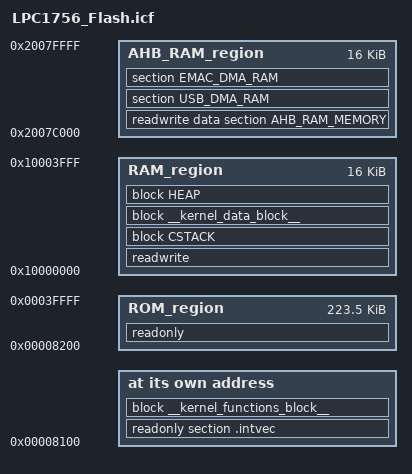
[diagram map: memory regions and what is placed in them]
/*###ICF### Section handled by ICF editor, don't touch! ****/
/*-Editor annotation file-*/
/* IcfEditorFile="$TOOLKIT_DIR$\config\ide\IcfEditor\cortex_v1_0.xml" */
/*-Specials-*/
define symbol __ICFEDIT_intvec_start__ = 0x00008100;
/*-Memory Regions-*/
define symbol __ICFEDIT_region_ROM_start__   = 0x00008200;
define symbol __ICFEDIT_region_ROM_end__     = 0x0003FFFF;
define symbol __ICFEDIT_region_RAM_start__   = 0x10000000;
define symbol __ICFEDIT_region_RAM_end__     = 0x10003FFF;
/*-Sizes-*/
define symbol __ICFEDIT_size_cstack__   = 0x800;
define symbol __ICFEDIT_size_heap__     = 0x400;
/**** End of ICF editor section. ###ICF###*/

define memory mem with size = 4G;
define region ROM_region   = mem:[from __ICFEDIT_region_ROM_start__   to __ICFEDIT_region_ROM_end__];
define region RAM_region   = mem:[from __ICFEDIT_region_RAM_start__   to __ICFEDIT_region_RAM_end__];

define symbol _AHB_RAM_start__  = 0x2007C000;
define symbol _AHB_RAM_end__    = 0x2007FFFF;
define region AHB_RAM_region = mem:[from _AHB_RAM_start__ to _AHB_RAM_end__];

define block CSTACK    with alignment = 8, size = __ICFEDIT_size_cstack__   { };
define block HEAP      with alignment = 8, size = __ICFEDIT_size_heap__     { };

initialize by copy { readwrite };
do not initialize  { section .noinit };
do not initialize  { section USB_DMA_RAM };

/* This must match the number of implemented vectors * 4 and be padded to an 8
byte boundary (check the mapfile to ensure that the kernel function region is
correctly occupying the first 8K region of flash). There does not seem to be any
way of dynamically determining the size of the vector table section at link time,
hence this direct definition. */
define symbol __size_vectors__              = 0xE8;

/* Define a block for the kernel's functions.  - __size_vectors__ because the
first part of the 8K is taken by the interrupt vectors. */
define block __kernel_functions_block__ with alignment = 8, size = 0x2000 - __size_vectors__ { section __kernel_functions__ };

/* Define a block for the kernel's data. */
define block __kernel_data_block__ with alignment = 0x400, size = 0x400 { section __kernel_data__ };


place at address mem:__ICFEDIT_intvec_start__ { readonly section .intvec, block __kernel_functions_block__ };

place in ROM_region   { readonly };
place in RAM_region   { readwrite,
                        block CSTACK, block __kernel_data_block__,  block HEAP };
place in AHB_RAM_region
                      { readwrite data section AHB_RAM_MEMORY, section USB_DMA_RAM,  section EMAC_DMA_RAM};


/* Export symbols required by c code. */
export symbol __ICFEDIT_intvec_start__;
export symbol __ICFEDIT_size_cstack__;
export symbol __ICFEDIT_region_ROM_start__;
export symbol __ICFEDIT_region_ROM_end__;
